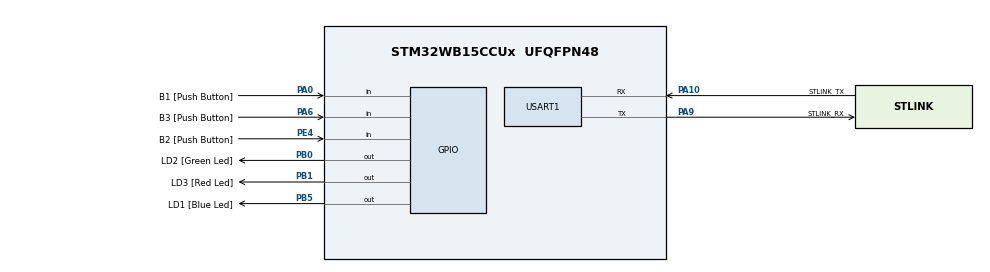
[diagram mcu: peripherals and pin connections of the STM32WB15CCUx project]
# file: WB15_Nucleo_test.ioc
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Dma.Request0=USART1_TX
Dma.USART1_TX.0.Direction=DMA_MEMORY_TO_PERIPH
Dma.USART1_TX.0.EventEnable=DISABLE
Dma.USART1_TX.0.Instance=DMA1_Channel4
Dma.USART1_TX.0.MemDataAlignment=DMA_MDATAALIGN_BYTE
Dma.USART1_TX.0.MemInc=DMA_MINC_ENABLE
Dma.USART1_TX.0.Mode=DMA_NORMAL
Dma.USART1_TX.0.PeriphDataAlignment=DMA_PDATAALIGN_BYTE
Dma.USART1_TX.0.PeriphInc=DMA_PINC_DISABLE
Dma.USART1_TX.0.Polarity=HAL_DMAMUX_REQ_GEN_RISING
Dma.USART1_TX.0.Priority=DMA_PRIORITY_LOW
Dma.USART1_TX.0.RequestNumber=1
Dma.USART1_TX.0.SignalID=NONE
Dma.USART1_TX.0.SyncEnable=DISABLE
Dma.USART1_TX.0.SyncPolarity=HAL_DMAMUX_SYNC_NO_EVENT
Dma.USART1_TX.0.SyncRequestNumber=1
Dma.USART1_TX.0.SyncSignalID=NONE
Mcu.Family=STM32WB
Mcu.Name=STM32WB15CCUx
Mcu.Package=UFQFPN48
NVIC.DMA1_Channel4_IRQn=true\:15\:0\:true\:false\:true\:false\:true
NVIC.HSEM_IRQn=true\:0\:0\:false\:false\:true\:false\:true
NVIC.IPCC_C1_RX_IRQn=true\:0\:0\:false\:false\:true\:true\:true
NVIC.IPCC_C1_TX_IRQn=true\:0\:0\:false\:false\:true\:true\:true
NVIC.PriorityGroup=NVIC_PRIORITYGROUP_4
NVIC.RTC_WKUP_IRQn=true\:0\:0\:false\:false\:true\:true\:true
NVIC.USART1_IRQn=true\:0\:0\:false\:false\:true\:true\:true
OSC_IN.Mode=HSE-External-Oscillator
OSC_IN.Signal=RCC_OSC_IN
OSC_OUT.Mode=HSE-External-Oscillator
OSC_OUT.Signal=RCC_OSC_OUT
PA0.GPIO_Label=B1 [Push Button]
PA0.Signal=GPIO_Input
PA10.GPIO_Label=STLINK_TX
PA10.GPIO_PuPd=GPIO_PULLUP
PA10.Mode=Asynchronous
PA10.Signal=USART1_RX
PA13.GPIO_Label=JTMS
PA13.Signal=SYS_JTMS-SWDIO
PA14.GPIO_Label=JTCK
PA14.Signal=SYS_JTCK-SWCLK
PA6.GPIO_Label=B3 [Push Button]
PA6.GPIO_PuPd=GPIO_PULLUP
PA6.Signal=GPIO_Input
PA9.GPIO_Label=STLINK_RX
PA9.GPIO_PuPd=GPIO_PULLUP
PA9.Mode=Asynchronous
PA9.Signal=USART1_TX
PB0.GPIO_Label=LD2 [Green Led]
PB0.Signal=GPIO_Output
PB1.GPIO_Label=LD3 [Red Led]
PB1.Signal=GPIO_Output
PB3.GPIO_Label=JTDO
PB3.Signal=SYS_JTDO-SWO
PB5.GPIO_Label=LD1 [Blue Led]
PB5.Signal=GPIO_Output
PC14-OSC32_IN.Mode=LSE-External-Oscillator
PC14-OSC32_IN.Signal=RCC_OSC32_IN
PC15-OSC32_OUT.Mode=LSE-External-Oscillator
PC15-OSC32_OUT.Signal=RCC_OSC32_OUT
PE4.GPIO_Label=B2 [Push Button]
PE4.GPIO_PuPd=GPIO_PULLUP
PE4.Signal=GPIO_Input
ProjectManager.HeapSize=0x200
ProjectManager.StackSize=0x400
ProjectManager.TargetToolchain=STM32CubeIDE
RCC.AHB2CLKDivider=RCC_SYSCLK_DIV2
RCC.AHBFreq_Value=64000000
RCC.APB1Freq_Value=64000000
RCC.APB1TimFreq_Value=64000000
RCC.APB2Freq_Value=64000000
RCC.APB2TimFreq_Value=64000000
RCC.APB3Freq_Value=16000000
RCC.CortexFreq_Value=64000000
RCC.HCLKFreq_Value=64000000
RCC.HSE_VALUE=32000000
RCC.HSI_VALUE=16000000
RCC.PLLN=32
RCC.SYSCLKFreq_VALUE=64000000
RCC.SYSCLKSource=RCC_SYSCLKSOURCE_PLLCLK
RCC.VCOOutputFreq_Value=128000000
RF1.Mode=RF1_Activate
RF1.Signal=RF_RF1
STM32_WPAN.BLE_DBG_P2P_STM_EN=1
STM32_WPAN.CFG_BLE_NUM_GATT_ATTRIBUTES=30
STM32_WPAN.CFG_BLE_NUM_GATT_SERVICES=4
STM32_WPAN.CFG_DEBUG_APP_TRACE=1
STM32_WPAN.CFG_DEBUG_BLE_TRACE=1
STM32_WPAN.CFG_DEBUG_TRACE_LIGHT=1
STM32_WPAN.CFG_DEBUG_TRACE_UART=hw_uart1
STM32_WPAN.CFG_HW_USART1_DMA_TX_SUPPORTED=1
STM32_WPAN.CFG_HW_USART1_ENABLED=1
USART1.VirtualMode-Asynchronous=VM_ASYNC
VP_HSEM_VS_HSEM.Mode=HSEM_Activate
VP_IPCC_VS_IPCC.Mode=IPCC_Activate
VP_RTC_VS_RTC_Activate.Mode=RTC_Enabled
VP_RTC_VS_RTC_WakeUp_intern.Mode=WakeUp
VP_SEQUENCER_VS_SEQUENCER.Mode=SEQUENCER_Enabled
VP_STM32_WPAN_VS_BLE_HOST.Mode=STM32_WPAN_Enabled
VP_TINY_LPM_VS_TINY_LPM.Mode=TINY_LPM_Enabled
board=NUCLEO-WB15CC

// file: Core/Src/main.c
/* USER CODE BEGIN Header */
/**
  ******************************************************************************
  * @file           : main.c
  * @brief          : Main program body
  ******************************************************************************
  * @attention
  *
  * <h2><center>&copy; Copyright (c) 2021 STMicroelectronics.
  * All rights reserved.</center></h2>
  *
  * This software component is licensed by ST under BSD 3-Clause license,
  * the "License"; You may not use this file except in compliance with the
  * License. You may obtain a copy of the License at:
  *                        opensource.org/licenses/BSD-3-Clause
  *
  ******************************************************************************
  */
/* USER CODE END Header */
#include "main.h"

IPCC_HandleTypeDef hipcc;

RTC_HandleTypeDef hrtc;

UART_HandleTypeDef huart1;
DMA_HandleTypeDef hdma_usart1_tx;

void SystemClock_Config(void);
static void MX_GPIO_Init(void);
static void MX_DMA_Init(void);
static void MX_RF_Init(void);
static void MX_RTC_Init(void);
static void MX_IPCC_Init(void);

int main(void)
{

  /* MCU Configuration--------------------------------------------------------*/

  /* Reset of all peripherals, Initializes the Flash interface and the Systick. */
  HAL_Init();
  /* Config code for STM32_WPAN (HSE Tuning must be done before system clock configuration) */
  MX_APPE_Config();

  /* Configure the system clock */
  SystemClock_Config();

  /* IPCC initialisation */
   MX_IPCC_Init();

  /* Initialize all configured peripherals */
  MX_GPIO_Init();
  MX_DMA_Init();
  MX_USART1_UART_Init();
  MX_RF_Init();
  MX_RTC_Init();
  /* USER CODE BEGIN 2 */
  // HAL_UART_Transmit(&huart1, "1234", 4, 1000);
  // HAL_UART_Transmit_IT(&huart1, "4567", 4);
  // HAL_UART_Transmit_DMA(&huart1, "8901", 4);
  /* USER CODE END 2 */

  /* Init code for STM32_WPAN */
  MX_APPE_Init();
  /* Infinite loop */
  while (1)
  {
    MX_APPE_Process();

  }
}

void SystemClock_Config(void)
{
  RCC_OscInitTypeDef RCC_OscInitStruct = {0};
  RCC_ClkInitTypeDef RCC_ClkInitStruct = {0};
  RCC_PeriphCLKInitTypeDef PeriphClkInitStruct = {0};

  /** Configure LSE Drive Capability
  */
  HAL_PWR_EnableBkUpAccess();
  __HAL_RCC_LSEDRIVE_CONFIG(RCC_LSEDRIVE_LOW);
  /** Initializes the RCC Oscillators according to the specified parameters
  * in the RCC_OscInitTypeDef structure.
  */
  RCC_OscInitStruct.OscillatorType = RCC_OSCILLATORTYPE_HSI|RCC_OSCILLATORTYPE_LSI1
                              |RCC_OSCILLATORTYPE_HSE|RCC_OSCILLATORTYPE_LSE
                              |RCC_OSCILLATORTYPE_MSI;
  RCC_OscInitStruct.HSEState = RCC_HSE_ON;
  RCC_OscInitStruct.LSEState = RCC_LSE_ON;
  RCC_OscInitStruct.HSIState = RCC_HSI_ON;
  RCC_OscInitStruct.MSIState = RCC_MSI_ON;
  RCC_OscInitStruct.HSICalibrationValue = RCC_HSICALIBRATION_DEFAULT;
  RCC_OscInitStruct.MSICalibrationValue = RCC_MSICALIBRATION_DEFAULT;
  RCC_OscInitStruct.MSIClockRange = RCC_MSIRANGE_6;
  RCC_OscInitStruct.LSIState = RCC_LSI_ON;
  RCC_OscInitStruct.PLL.PLLState = RCC_PLL_ON;
  RCC_OscInitStruct.PLL.PLLSource = RCC_PLLSOURCE_MSI;
  RCC_OscInitStruct.PLL.PLLM = RCC_PLLM_DIV1;
  RCC_OscInitStruct.PLL.PLLN = 32;
  RCC_OscInitStruct.PLL.PLLP = RCC_PLLP_DIV2;
  RCC_OscInitStruct.PLL.PLLR = RCC_PLLR_DIV2;
  RCC_OscInitStruct.PLL.PLLQ = RCC_PLLQ_DIV2;
  if (HAL_RCC_OscConfig(&RCC_OscInitStruct) != HAL_OK)
  {
    Error_Handler();
  }
  /** Configure the SYSCLKSource, HCLK, PCLK1 and PCLK2 clocks dividers
  */
  RCC_ClkInitStruct.ClockType = RCC_CLOCKTYPE_HCLK4|RCC_CLOCKTYPE_HCLK2
                              |RCC_CLOCKTYPE_HCLK|RCC_CLOCKTYPE_SYSCLK
                              |RCC_CLOCKTYPE_PCLK1|RCC_CLOCKTYPE_PCLK2;
  RCC_ClkInitStruct.SYSCLKSource = RCC_SYSCLKSOURCE_PLLCLK;
  RCC_ClkInitStruct.AHBCLKDivider = RCC_SYSCLK_DIV1;
  RCC_ClkInitStruct.APB1CLKDivider = RCC_HCLK_DIV1;
  RCC_ClkInitStruct.APB2CLKDivider = RCC_HCLK_DIV1;
  RCC_ClkInitStruct.AHBCLK2Divider = RCC_SYSCLK_DIV2;
  RCC_ClkInitStruct.AHBCLK4Divider = RCC_SYSCLK_DIV1;

  if (HAL_RCC_ClockConfig(&RCC_ClkInitStruct, FLASH_LATENCY_3) != HAL_OK)
  {
    Error_Handler();
  }
  /** Initializes the peripherals clocks
  */
  PeriphClkInitStruct.PeriphClockSelection = RCC_PERIPHCLK_SMPS|RCC_PERIPHCLK_RFWAKEUP
                              |RCC_PERIPHCLK_RTC|RCC_PERIPHCLK_USART1;
  PeriphClkInitStruct.Usart1ClockSelection = RCC_USART1CLKSOURCE_PCLK2;
  PeriphClkInitStruct.RTCClockSelection = RCC_RTCCLKSOURCE_LSI;
  PeriphClkInitStruct.RFWakeUpClockSelection = RCC_RFWKPCLKSOURCE_LSE;
  PeriphClkInitStruct.SmpsClockSelection = RCC_SMPSCLKSOURCE_HSI;
  PeriphClkInitStruct.SmpsDivSelection = RCC_SMPSCLKDIV_RANGE1;
  if (HAL_RCCEx_PeriphCLKConfig(&PeriphClkInitStruct) != HAL_OK)
  {
    Error_Handler();
  }
  /** Enable MSI Auto calibration
  */
  HAL_RCCEx_EnableMSIPLLMode();
}

static void MX_IPCC_Init(void)
{

  hipcc.Instance = IPCC;
  if (HAL_IPCC_Init(&hipcc) != HAL_OK)
  {
    Error_Handler();
  }

}

static void MX_RF_Init(void)
{

}

static void MX_RTC_Init(void)
{

  /** Initialize RTC Only
  */
  hrtc.Instance = RTC;
  hrtc.Init.HourFormat = RTC_HOURFORMAT_24;
  hrtc.Init.AsynchPrediv = CFG_RTC_ASYNCH_PRESCALER;
  hrtc.Init.SynchPrediv = CFG_RTC_SYNCH_PRESCALER;
  hrtc.Init.OutPut = RTC_OUTPUT_DISABLE;
  hrtc.Init.OutPutPolarity = RTC_OUTPUT_POLARITY_HIGH;
  hrtc.Init.OutPutRemap = RTC_OUTPUT_REMAP_NONE;
  if (HAL_RTC_Init(&hrtc) != HAL_OK)
  {
    Error_Handler();
  }
  /** Enable the WakeUp
  */
  if (HAL_RTCEx_SetWakeUpTimer_IT(&hrtc, 0, RTC_WAKEUPCLOCK_RTCCLK_DIV16) != HAL_OK)
  {
    Error_Handler();
  }

}

void MX_USART1_UART_Init(void)
{

  huart1.Instance = USART1;
  huart1.Init.BaudRate = 115200;
  huart1.Init.WordLength = UART_WORDLENGTH_8B;
  huart1.Init.StopBits = UART_STOPBITS_1;
  huart1.Init.Parity = UART_PARITY_NONE;
  huart1.Init.Mode = UART_MODE_TX_RX;
  huart1.Init.HwFlowCtl = UART_HWCONTROL_NONE;
  huart1.Init.OverSampling = UART_OVERSAMPLING_8;
  huart1.Init.OneBitSampling = UART_ONE_BIT_SAMPLE_DISABLE;
  huart1.Init.ClockPrescaler = UART_PRESCALER_DIV1;
  huart1.AdvancedInit.AdvFeatureInit = UART_ADVFEATURE_NO_INIT;
  if (HAL_UART_Init(&huart1) != HAL_OK)
  {
    Error_Handler();
  }
  if (HAL_UARTEx_SetTxFifoThreshold(&huart1, UART_TXFIFO_THRESHOLD_1_8) != HAL_OK)
  {
    Error_Handler();
  }
  if (HAL_UARTEx_SetRxFifoThreshold(&huart1, UART_RXFIFO_THRESHOLD_1_8) != HAL_OK)
  {
    Error_Handler();
  }
  if (HAL_UARTEx_DisableFifoMode(&huart1) != HAL_OK)
  {
    Error_Handler();
  }

}

static void MX_DMA_Init(void)
{

  /* DMA controller clock enable */
  __HAL_RCC_DMAMUX1_CLK_ENABLE();
  __HAL_RCC_DMA1_CLK_ENABLE();

  /* DMA interrupt init */
  /* DMA1_Channel4_IRQn interrupt configuration */
  HAL_NVIC_SetPriority(DMA1_Channel4_IRQn, 15, 0);
  HAL_NVIC_EnableIRQ(DMA1_Channel4_IRQn);

}

static void MX_GPIO_Init(void)
{
  GPIO_InitTypeDef GPIO_InitStruct = {0};

  /* GPIO Ports Clock Enable */
  __HAL_RCC_GPIOC_CLK_ENABLE();
  __HAL_RCC_GPIOA_CLK_ENABLE();
  __HAL_RCC_GPIOB_CLK_ENABLE();
  __HAL_RCC_GPIOE_CLK_ENABLE();

  /*Configure GPIO pin Output Level */
  HAL_GPIO_WritePin(GPIOB, LD2_Pin|LD3_Pin|LD1_Pin, GPIO_PIN_RESET);

  /*Configure GPIO pin : B1_Pin */
  GPIO_InitStruct.Pin = B1_Pin;
  GPIO_InitStruct.Mode = GPIO_MODE_INPUT;
  GPIO_InitStruct.Pull = GPIO_NOPULL;
  HAL_GPIO_Init(B1_GPIO_Port, &GPIO_InitStruct);

  /*Configure GPIO pin : B3_Pin */
  GPIO_InitStruct.Pin = B3_Pin;
  GPIO_InitStruct.Mode = GPIO_MODE_INPUT;
  GPIO_InitStruct.Pull = GPIO_PULLUP;
  HAL_GPIO_Init(B3_GPIO_Port, &GPIO_InitStruct);

  /*Configure GPIO pins : LD2_Pin LD3_Pin LD1_Pin */
  GPIO_InitStruct.Pin = LD2_Pin|LD3_Pin|LD1_Pin;
  GPIO_InitStruct.Mode = GPIO_MODE_OUTPUT_PP;
  GPIO_InitStruct.Pull = GPIO_NOPULL;
  GPIO_InitStruct.Speed = GPIO_SPEED_FREQ_LOW;
  HAL_GPIO_Init(GPIOB, &GPIO_InitStruct);

  /*Configure GPIO pin : B2_Pin */
  GPIO_InitStruct.Pin = B2_Pin;
  GPIO_InitStruct.Mode = GPIO_MODE_INPUT;
  GPIO_InitStruct.Pull = GPIO_PULLUP;
  HAL_GPIO_Init(B2_GPIO_Port, &GPIO_InitStruct);

}

void Error_Handler(void)
{
  __disable_irq();
  while (1)
  {
  }
}

/************************ (C) COPYRIGHT STMicroelectronics *****END OF FILE****/
